# WS63 register map
File version: 1.0
CPU: other r0p0, little endian, MPU, FPU, 3 interrupt priority bits
Registers are 32-bit, read-write, reset 0x0 unless marked. A register's access mark holds for its fields unless they carry their own. Offsets are from the block's base; [hi:lo] are bit positions; {n}, {i} and the like mark numbered series.

## SFC_CFG — SPI Flash Controller configuration
Base 0x48000000
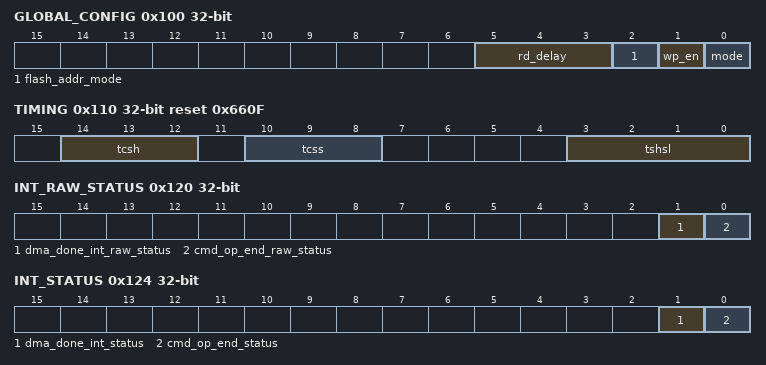
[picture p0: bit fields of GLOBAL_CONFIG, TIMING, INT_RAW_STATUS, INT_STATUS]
0x100 GLOBAL_CONFIG — Global configuration register
  [5:3] rd_delay — SPI read data delay: 000=0.5~1clk; 001=1~1.5clk; etc.
  [2] flash_addr_mode — Address mode: 0=3byte; 1=4byte. NOTE: write has no effect when CMD_CONFIG[start]=1
    0=Addr3Byte (3-byte addressing); 1=Addr4Byte (4-byte addressing)
  [1] wp_en — Hardware write protect: 0=disabled; 1=enabled
  [0] mode — SPI mode: 0=Mode0; 1=Mode3
    0=SPI Mode 0 (CPOL=0, CPHA=0); 1=SPI Mode 3 (CPOL=1, CPHA=1)
0x110 TIMING reset 0x660F — Timing configuration register
  [14:12] tcsh — CS hold time: (n+1) clock cycles
  [10:8] tcss — CS setup time: (n+1) clock cycles
  [3:0] tshsl — Inter-operation delay: (n+2) clock cycles
0x120 INT_RAW_STATUS — Interrupt raw status register
  [1] dma_done_int_raw_status ro — DMA done raw status
  [0] cmd_op_end_raw_status ro — Command operation end raw status
0x124 INT_STATUS — Interrupt status register (masked)
  [1] dma_done_int_status ro — DMA done status
  [0] cmd_op_end_status ro — Command operation end status
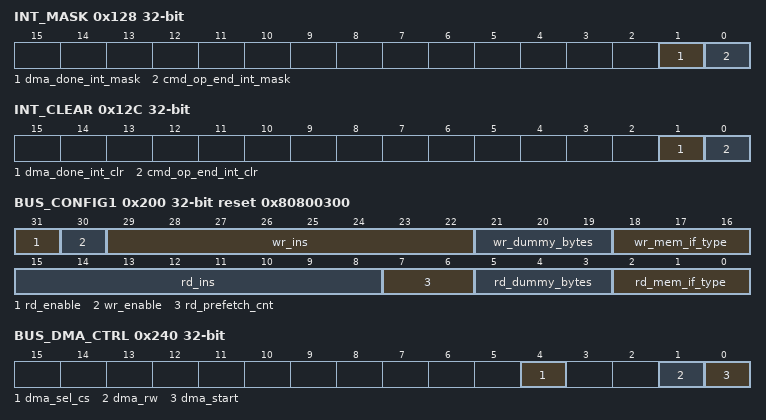
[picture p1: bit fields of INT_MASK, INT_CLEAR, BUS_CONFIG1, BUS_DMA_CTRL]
0x128 INT_MASK — Interrupt mask register
  [1] dma_done_int_mask — DMA done mask
  [0] cmd_op_end_int_mask — Command end mask: 0=masked; 1=unmasked
0x12C INT_CLEAR — Interrupt clear register
  [1] dma_done_int_clr wo — DMA done interrupt clear (self-clearing)
  [0] cmd_op_end_int_clr wo — Command end interrupt clear (self-clearing)
0x130 SOFT_RST_MASK reset 0x1 — Soft reset mask register
  [0] sfc_bus_soft_rst_mask — SFC bus soft reset mask: 0=reset active; 1=reset masked
0x200 BUS_CONFIG1 reset 0x80800300 — Bus operation config 1
  [31] rd_enable — Bus read enable
  [30] wr_enable — Bus write enable
  [29:22] wr_ins — Write instruction code
  [21:19] wr_dummy_bytes — Write dummy bytes
  [18:16] wr_mem_if_type — Write SPI interface type
  [15:8] rd_ins — Read instruction code
  [7:6] rd_prefetch_cnt — Read prefetch count: 00=none; 01=1clk; 10=2clk; 11=3clk
  [5:3] rd_dummy_bytes — Read dummy bytes: 000=0; 001=1; etc.
  [2:0] rd_mem_if_type — Read SPI interface type: 000=Standard; 001=Dual I/O; 010=Dual-IO; 101=Quad-Input; 110=Quad-IO
0x204 BUS_CONFIG2 — Bus operation config 2
  [2:0] wip_locate — WIP bit position in Flash status register: 000=bit0; etc.
0x240 BUS_DMA_CTRL — DMA operation control register
  [4] dma_sel_cs — DMA chip select: 0=CS0; 1=CS1
  [1] dma_rw — DMA direction: 0=write; 1=read
  [0] dma_start — DMA transfer enable (auto-clears)
0x244 BUS_DMA_MEM_SADDR — DMA memory start address
  [31:0] dma_mem_saddr — DMA memory start address (0x00100000~0x00BFFFFF)
0x248 BUS_DMA_FLASH_SADDR — DMA Flash start address
  [31:0] dma_flash_saddr
0x24C BUS_DMA_LEN — DMA transfer length
  [29:0] dma_len — DMA length (n+1 bytes)
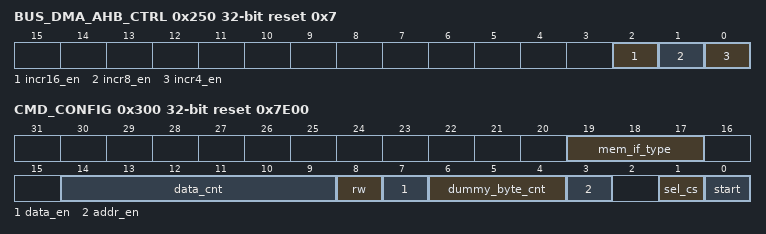
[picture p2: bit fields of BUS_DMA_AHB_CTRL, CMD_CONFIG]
0x250 BUS_DMA_AHB_CTRL reset 0x7 — DMA AHB burst control
  [2] incr16_en — INCR16 burst enable
  [1] incr8_en — INCR8 burst enable
  [0] incr4_en — INCR4 burst enable
0x300 CMD_CONFIG reset 0x7E00 — Command operation config
  [19:17] mem_if_type — SPI interface type: 000=Standard; 001=Dual; 010=Dual-IO; 101=Quad-Input; 110=Quad-IO
  [14:9] data_cnt — Data length (n+1 bytes)
  [8] rw — Data direction: 0=write; 1=read
  [7] data_en — Data present: 0=no; 1=yes
  [6:4] dummy_byte_cnt — Dummy bytes: 000=0; 001=1; etc.
  [3] addr_en — Address present: 0=no; 1=yes
  [1] sel_cs — Chip select: 0=CS0; 1=CS1
  [0] start — Command start (auto-clears)
0x308 CMD_INS — Command instruction register
  [7:0] reg_ins — Instruction code
0x30C CMD_ADDR — Command address register
  [29:0] cmd_addr — Operation address
0x400 CMD_DATABUF_0 — Command data buffer 0
  [31:0] cmd_databuf_0 — Data buffer 0
{0x400+4i} CMD_DATABUF_{i} (i=1..15) — Command data buffer {i}
0x1300 LEA_LP_EN reset 0x1 — LEA control register
  [0] lea_lp_en — AES low power: 0=disabled; 1=enabled
0x1304 LEA_DFX_INFO — LEA DFX register
  [31:0] lea_dfx_info ro — AES DFX observation
0x1600 LEA_IV_VLD — LEA IV valid register
  [0] lea_iv_vld — AES IV value valid (auto-clears after sync)
